VERSION ""

NS_ :

BS_:

BU_: Gateway IVI DMS BCM

BO_ 996 VCU_IVI_Msg: 1 Gateway
 SG_ ECall_Req : 1|1@1+ (1,0) [0|1] ""  IVI
 SG_ EDSS_Act : 0|1@1+ (1,0) [0|1] ""  IVI

BO_ 1010 BCM_Side_Road_State: 1 BCM
 SG_ Side_Road_State : 0|1@1+ (1,0) [0|1] ""  Gateway

BO_ 1009 BCM_Rear_Vehicle_State: 1 BCM
 SG_ Rear_Vehicle_state : 0|1@1+ (1,0) [0|1] ""  Gateway

BO_ 769 BCM_5s: 1 BCM
 SG_ Count_5s : 0|1@1+ (1,0) [0|1] ""  Gateway

BO_ 995 BCW_Data: 2 Gateway
 SG_ BCWState : 2|2@1+ (1,0) [0|3] ""  IVI
 SG_ BCW_LR : 0|2@1+ (1,0) [0|3] ""  IVI

BO_ 994 FCA_Data: 1 Gateway
 SG_ FCAState : 0|2@1+ (1,0) [0|3] ""  IVI

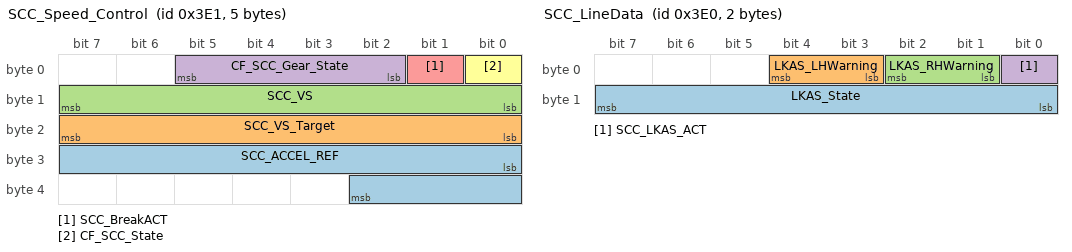
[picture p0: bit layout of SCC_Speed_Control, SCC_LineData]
BO_ 993 SCC_Speed_Control: 5 Gateway
 SG_ SCC_ACCEL_REF : 24|11@1+ (1,0) [0|2047] ""  IVI
 SG_ SCC_VS_Target : 16|8@1+ (1,0) [0|255] ""  IVI
 SG_ SCC_VS : 8|8@1+ (1,0) [0|255] ""  IVI
 SG_ CF_SCC_Gear_State : 2|4@1+ (1,0) [0|15] ""  IVI
 SG_ SCC_BreakACT : 1|1@1+ (1,0) [0|1] ""  IVI
 SG_ CF_SCC_State : 0|1@1+ (1,0) [0|1] ""  IVI

BO_ 992 SCC_LineData: 2 Gateway
 SG_ LKAS_State : 8|8@1+ (1,0) [0|255] ""  IVI
 SG_ LKAS_LHWarning : 3|2@1+ (1,0) [0|3] ""  IVI
 SG_ LKAS_RHWarning : 1|2@1+ (1,0) [0|3] ""  IVI
 SG_ SCC_LKAS_ACT : 0|1@1+ (1,0) [0|1] ""  IVI

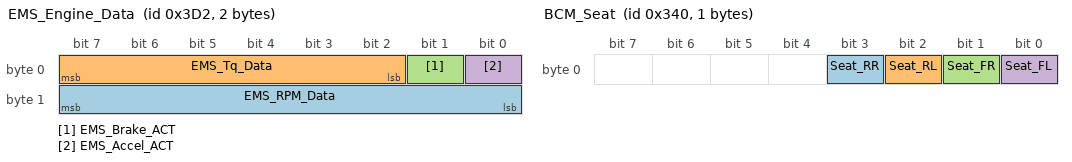
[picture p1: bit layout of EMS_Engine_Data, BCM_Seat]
BO_ 978 EMS_Engine_Data: 2 Gateway
 SG_ EMS_RPM_Data : 8|8@1+ (1,0) [0|255] ""  IVI
 SG_ EMS_Tq_Data : 2|6@1+ (1,0) [0|63] ""  IVI
 SG_ EMS_Brake_ACT : 1|1@1+ (1,0) [0|1] ""  IVI
 SG_ EMS_Accel_ACT : 0|1@1+ (1,0) [0|1] ""  IVI

BO_ 977 EPB_State_Data: 1 Gateway
 SG_ EPB_ACT : 1|1@1+ (1,0) [0|1] ""  IVI
 SG_ EPB_State : 0|1@1+ (1,0) [0|1] ""  IVI

BO_ 976 TCU_Gear_Data: 2 Gateway
 SG_ TCU_GearType : 1|15@1+ (1,0) [0|65535] ""  IVI
 SG_ TCU_GearState : 0|1@1+ (1,0) [0|1] ""  IVI

BO_ 964 VCU_Ecall_State: 1 Gateway
 SG_ Ecall_State : 0|1@1+ (1,0) [0|1] ""  IVI

BO_ 963 VCU_EDSS_State: 1 Gateway
 SG_ EDSS_State : 0|1@1+ (1,0) [0|1] ""  IVI

BO_ 962 VCU_WarningState_Timeout: 1 Gateway
 SG_ WarningState_Timeout : 0|3@1+ (1,0) [0|7] ""  IVI

BO_ 961 VCU_WarningSign_Cmd: 1 Gateway
 SG_ WarningSign_Lv : 0|3@1+ (1,0) [0|7] ""  IVI

BO_ 960 VCU_WarningSign_State: 1 Gateway
 SG_ WarningSign_State : 0|1@1+ (1,0) [0|1] ""  IVI

BO_ 944 VCU_SafeBelt_State: 1 Gateway
 SG_ SafeBelt_State : 0|1@1+ (1,0) [0|1] ""  BCM

BO_ 1008 VCU_Steering_Vibration_Sate: 1 Gateway
 SG_ Steering_Vibration_Sate : 0|1@1+ (1,0) [0|1] ""  BCM

BO_ 913 VCU_Horn_Cmd: 2 Gateway
 SG_ Horn_Period : 8|8@1+ (1,0) [0|255] ""  BCM
 SG_ Horn_Sound : 0|8@1+ (1,0) [0|255] ""  BCM

BO_ 912 VCU_Horn_State: 1 Gateway
 SG_ Horn_State : 0|1@1+ (1,0) [0|1] ""  BCM

BO_ 897 VCU_Hazard_Light_Cmd: 1 Gateway
 SG_ Hazard_Light_Duty : 0|8@1+ (1,0) [0|255] ""  BCM

BO_ 896 VCU_Hazard_Light_State: 1 Gateway
 SG_ Hazard_Light_State : 0|1@1+ (1,0) [0|1] ""  BCM

BO_ 881 VCU_MoodLED_Cmd: 2 Gateway
 SG_ MoodLED_Duty : 8|8@1+ (1,0) [0|255] ""  BCM
 SG_ MoodLed_Pos : 0|3@1+ (1,0) [0|7] ""  BCM

BO_ 880 VCU_MoodLED_State: 1 Gateway
 SG_ MoodLED_State : 0|1@1+ (1,0) [0|1] ""  BCM

BO_ 82 IVI_NM_Flag: 1 IVI
 SG_ NmSleepFlag_IVI : 0|1@1+ (1,0) [0|1] ""  Gateway

BO_ 81 DMS_NM_Flag: 1 DMS
 SG_ NmSleepFlag_DMS : 0|1@1+ (1,0) [0|1] ""  Gateway

BO_ 80 BCM_NM_Flag: 1 BCM
 SG_ NmSleepFlag_BCM : 0|1@1+ (1,0) [0|1] ""  Gateway

BO_ 66 GW_NM_IVI: 1 Gateway
 SG_ NmSleepCmd_IVI : 0|1@1+ (1,0) [0|1] ""  IVI

BO_ 65 GW_NM_DMS: 1 Gateway
 SG_ NmSleepCmd_DMS : 0|1@1+ (1,0) [0|1] ""  DMS

BO_ 64 GW_NM_BCM: 1 Gateway
 SG_ NmSleepCmd_BCM : 0|1@1+ (1,0) [0|1] ""  BCM

BO_ 48 VCU_IGN1: 1 Gateway
 SG_ IGN_State : 0|1@1+ (1,0) [0|1] ""  IVI,DMS,BCM

BO_ 865 BCM_Steering_Pos: 1 BCM
 SG_ Str_Pos : 0|6@1+ (1,0) [0|63] ""  Gateway

BO_ 864 BCM_Steering_Holding: 1 BCM
 SG_ Str_Hold : 0|1@1+ (1,0) [0|1] ""  Gateway

BO_ 849 BCM_AirBag_Pos: 1 BCM
 SG_ AirBag_Pos : 0|3@1+ (1,0) [0|7] ""  Gateway

BO_ 848 BCM_AirBag_state: 1 BCM
 SG_ AirBag_state : 0|1@1+ (1,0) [0|1] ""  Gateway

BO_ 832 BCM_Seat: 1 BCM
 SG_ Seat_RR : 3|1@1+ (1,0) [0|1] ""  Gateway
 SG_ Seat_RL : 2|1@1+ (1,0) [0|1] ""  Gateway
 SG_ Seat_FR : 1|1@1+ (1,0) [0|1] ""  Gateway
 SG_ Seat_FL : 0|1@1+ (1,0) [0|1] ""  Gateway

BO_ 817 IVI_EDSS_CSW: 1 IVI
 SG_ IVI_EDSS_CANCEL_SW : 0|1@1+ (1,0) [0|1] ""  Gateway

BO_ 816 BCM_EDSS_CSW: 1 BCM
 SG_ BCM_EDSS_CANCEL_SW : 0|1@1+ (1,0) [0|1] ""  Gateway

BO_ 800 DMS_Driver_State: 1 DMS
 SG_ DMS_CautionLv : 0|3@1+ (1,0) [0|7] "lv"  Gateway,IVI

BO_ 787 BCM_Wheel_Speed_RR: 1 BCM
 SG_ Wheel_Speed_RR : 0|8@1+ (1,0) [0|255] "km"  Gateway

BO_ 786 BCM_Wheel_Speed_RL: 1 BCM
 SG_ Wheel_Speed_RL : 0|8@1+ (1,0) [0|255] "km"  Gateway

BO_ 785 BCM_Wheel_Speed_FR: 1 BCM
 SG_ Wheel_Speed_FR : 0|8@1+ (1,0) [0|255] "km"  Gateway

BO_ 784 BCM_Wheel_Speed_FL: 1 BCM
 SG_ Wheel_Speed_FL : 0|8@1+ (1,0) [0|255] "km/h"  Gateway

BO_ 768 BCM_EDSS_SW_STATE: 1 BCM
 SG_ EDSS_Passenger_On_Off : 1|1@1+ (1,0) [0|1] ""  Gateway
 SG_ EDSS_Driver_On_Off : 0|1@1+ (1,0) [0|1] ""  Gateway

BA_DEF_  "BusType" STRING ;
BA_DEF_DEF_  "BusType" "CAN";
